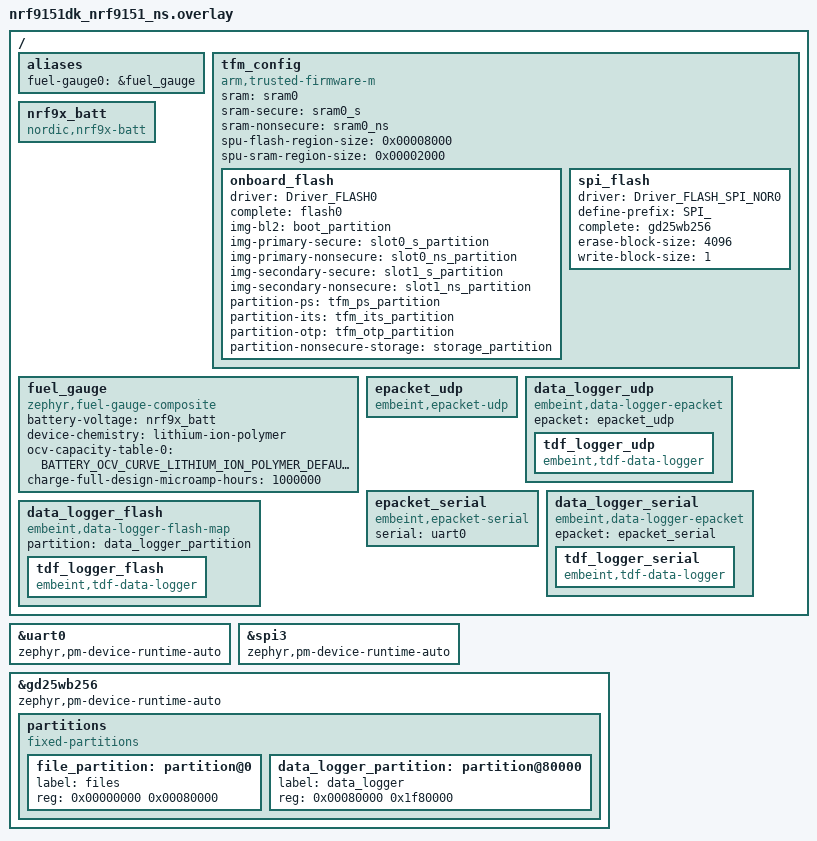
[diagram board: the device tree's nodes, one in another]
#include <zephyr/dt-bindings/battery/battery.h>
#include <common/nordic/infuse_nrf9151_ns.dtsi>

/ {
	aliases {
		fuel-gauge0 = &fuel_gauge;
	};

	tfm_config {
		compatible = "arm,trusted-firmware-m";
		sram = <&sram0>;
		sram-secure = <&sram0_s>;
		sram-nonsecure = <&sram0_ns>;
		spu-flash-region-size = <0x00008000>;
		spu-sram-region-size = <0x00002000>;

		onboard_flash {
			driver = "Driver_FLASH0";
			complete = <&flash0>;
			img-bl2 = <&boot_partition>;
			img-primary-secure = <&slot0_s_partition>;
			img-primary-nonsecure = <&slot0_ns_partition>;
			img-secondary-secure = <&slot1_s_partition>;
			img-secondary-nonsecure = <&slot1_ns_partition>;
			partition-ps = <&tfm_ps_partition>;
			partition-its = <&tfm_its_partition>;
			partition-otp = <&tfm_otp_partition>;
			partition-nonsecure-storage = <&storage_partition>;
		};

		spi_flash {
			driver = "Driver_FLASH_SPI_NOR0";
			define-prefix = "SPI_";
			complete = <&gd25wb256>;
			erase-block-size = <4096>;
			write-block-size = <1>;
		};
	};

	nrf9x_batt: nrf9x_batt {
		compatible = "nordic,nrf9x-batt";
	};

	fuel_gauge: fuel_gauge {
		compatible = "zephyr,fuel-gauge-composite";
		battery-voltage = <&nrf9x_batt>;
		device-chemistry = "lithium-ion-polymer";
		ocv-capacity-table-0 = <BATTERY_OCV_CURVE_LITHIUM_ION_POLYMER_DEFAULT>;
		charge-full-design-microamp-hours = <1000000>;
	};

	epacket_udp: epacket_udp {
		compatible = "embeint,epacket-udp";
	};

	data_logger_udp: data_logger_udp {
		compatible = "embeint,data-logger-epacket", "embeint,data-logger";
		epacket = <&epacket_udp>;

		tdf_logger_udp: tdf_logger_udp {
			compatible = "embeint,tdf-data-logger";
		};
	};

	epacket_serial: epacket_serial {
		compatible = "embeint,epacket-serial";
		serial = <&uart0>;
	};

	data_logger_serial: data_logger_serial {
		compatible = "embeint,data-logger-epacket", "embeint,data-logger";
		epacket = <&epacket_serial>;

		tdf_logger_serial: tdf_logger_serial {
			compatible = "embeint,tdf-data-logger";
		};
	};

	data_logger_flash: data_logger_flash {
		compatible = "embeint,data-logger-flash-map", "embeint,data-logger";
		partition = <&data_logger_partition>;

		tdf_logger_flash: tdf_logger_flash {
			compatible = "embeint,tdf-data-logger";
		};
	};
};

&uart0 {
	zephyr,pm-device-runtime-auto;
};

&spi3 {
	zephyr,pm-device-runtime-auto;
};

&gd25wb256 {
	zephyr,pm-device-runtime-auto;

	partitions {
		compatible = "fixed-partitions";
		#address-cells = <1>;
		#size-cells = <1>;

		file_partition: partition@0 {
			label = "files";
			reg = <0x00000000 0x00080000>;
		};
		data_logger_partition: partition@80000 {
			label = "data_logger";
			reg = <0x00080000 0x1f80000>;
		};
	};
};
